# ESP32S31_RADIO register map
Vendor: Espressif; Series: ESP32-S31; File version: 3.52
Registers are 32-bit, read-write, no defined reset value unless marked. A register's access mark holds for its fields unless they carry their own. Offsets are from the block's base; [hi:lo] are bit positions.

## WIFI_MAC_RTC_TIMER_UPDATE — Complete enabled path of hal_timer_update_by_rtc, reached from complete hal_init with enable one and the OS-adapter slow-clock calibration value.
Base 0x2010D830
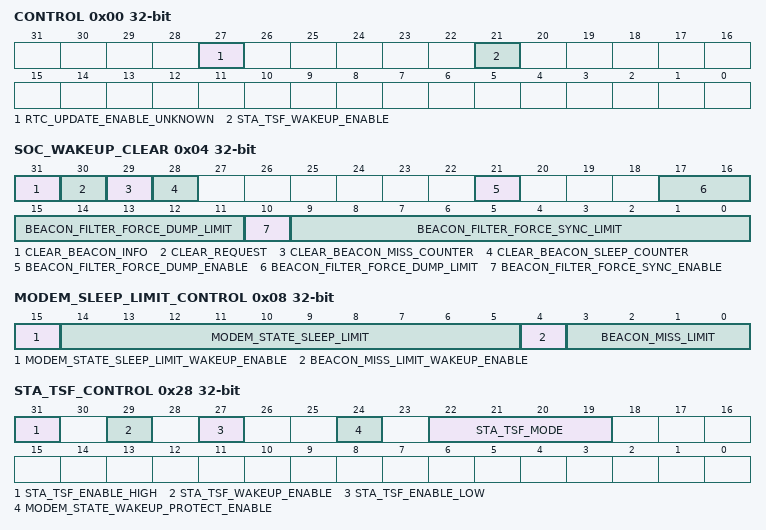
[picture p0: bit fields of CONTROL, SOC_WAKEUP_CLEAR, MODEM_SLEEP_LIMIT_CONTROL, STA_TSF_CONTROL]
0x00 CONTROL — Enabled hal_timer_update_by_rtc sets bit 27. hal_set_sta_tsf_wakeup sets or clears bit 21 together with the STA TSF wakeup bit at 0x2010d858.
  [27] RTC_UPDATE_ENABLE_UNKNOWN — Set when the leaf's enable argument is nonzero.
  [21] STA_TSF_WAKEUP_ENABLE — hal_set_sta_tsf_wakeup sets or clears this bit in the same branch as STA_TSF_CONTROL.STA_TSF_WAKEUP_ENABLE.
0x04 SOC_WAKEUP_CLEAR — Complete hal_tsf_clear_soc_wakeup_request sets bit 30. Complete modem-power leaves independently expose status bits and clear pulses in this shared word; hardware transition behavior is not inferred.
  [31] CLEAR_BEACON_INFO — Dedicated clear leaf sets bit 31.
  [30] CLEAR_REQUEST
  [29] CLEAR_BEACON_MISS_COUNTER — Dedicated clear leaf sets bit 29.
  [28] CLEAR_BEACON_SLEEP_COUNTER — Dedicated clear leaf sets bit 28.
  [21] BEACON_FILTER_FORCE_DUMP_ENABLE — Dedicated enable/disable leaves set or clear bit 21.
  [17:11] BEACON_FILTER_FORCE_DUMP_LIMIT — The dedicated setter replaces bits 17:11.
  [10] BEACON_FILTER_FORCE_SYNC_ENABLE — Dedicated enable/disable leaves set or clear bit 10.
  [9:0] BEACON_FILTER_FORCE_SYNC_LIMIT — The dedicated setter replaces bits 9:0.
0x08 MODEM_SLEEP_LIMIT_CONTROL — Complete no-call setters prove two bounded modem counters and their independent limit-exceeded wake gates. Units and hardware transition behavior remain unknown.
  [15] MODEM_STATE_SLEEP_LIMIT_WAKEUP_ENABLE — Dedicated enable/disable leaves set or clear bit fifteen.
  [14:5] MODEM_STATE_SLEEP_LIMIT — Low ten argument bits published in bits 14:5 by pwr_hal_set_mac_modem_state_sleep_limit.
  [4] BEACON_MISS_LIMIT_WAKEUP_ENABLE — Dedicated enable/disable leaves set or clear bit four.
  [3:0] BEACON_MISS_LIMIT — Low four argument bits published by pwr_hal_set_mac_modem_beacon_miss_limit.
0x10 STA_LIGHT_SLEEP_WAKE_AHEAD — Complete hal_set_sta_light_sleep_wake_ahead_time replaces the high sixteen bits. Complete hal_set_sta_tbtt independently publishes its fifth argument to the same field.
  [31:16] TIME
0x14 TBTT_RF_CONTROL_WAIT_CYCLES — Complete tsf_hal_set_tbtt_rf_ctrl_wait_cycles replaces the low twenty-four bits; units and hardware transition behavior remain unknown.
  [23:0] WAIT_CYCLES
0x24 RX_BEACON_TIME_LOW — Complete hal_set_rx_beacon_time and pwr_hal_set_mac_modem_beacon_miss_timeout independently replace the same low sixteen bits. The mode-dependent hardware interpretation is not inferred.
  [15:0] VALUE
0x28 STA_TSF_CONTROL — Shared STA TSF scheduler and modem-state wakeup control word used by hal_enable_sta_tsf, hal_disable_sta_tsf, hal_set_sta_tsf_wakeup, and the wakeup-protect enable/disable leaves.
  [31] STA_TSF_ENABLE_HIGH — hal_enable_sta_tsf sets this bit and hal_disable_sta_tsf clears it.
  [29] STA_TSF_WAKEUP_ENABLE — hal_set_sta_tsf_wakeup sets or clears this bit together with WIFI_MAC_RTC_TIMER_UPDATE.CONTROL.STA_TSF_WAKEUP_ENABLE.
  [27] STA_TSF_ENABLE_LOW — hal_enable_sta_tsf sets this bit and hal_disable_sta_tsf clears it.
  [24] MODEM_STATE_WAKEUP_PROTECT_ENABLE — pwr_hal_set_mac_modem_state_wakeup_protect_enable sets this bit and the corresponding disable leaf clears it.
  [22:19] STA_TSF_MODE — hal_enable_sta_tsf replaces bits 22:19 with one; hal_disable_sta_tsf clears them.
    0=DISABLED; 1=ENABLED
0x2C STA_TBTT_INTERVAL — Complete hal_set_sta_tbtt_interval replaces the low 22 bits from argument bits 31:10. Complete hal_set_sta_tbtt performs the same update from its third argument.
  [21:0] INTERVAL_BITS_31_10
0x48 SLOW_CLOCK_CALIBRATION — Enabled hal_timer_update_by_rtc replaces bits 17:0 with the low eighteen bits returned by g_wifi_osi_funcs._slowclk_cal_get.
  [17:0] VALUE — Any eighteen-bit value returned by the OS-adapter calibration callback is published without interpretation.
